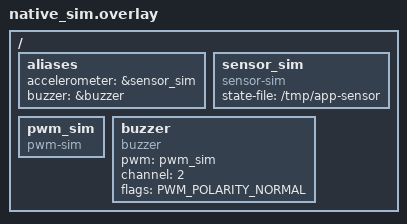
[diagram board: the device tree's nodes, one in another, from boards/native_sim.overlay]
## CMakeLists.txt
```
cmake_minimum_required(VERSION 3.20.0)

find_package(Zephyr REQUIRED HINTS $ENV{ZEPHYR_BASE})
project(workshop)

target_sources(app PRIVATE
    src/main.c
    src/serial_dfu.c
)
```

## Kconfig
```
menu "Application"

config APP_HELLO_WORLD_MSG
	string "Hello World Message"
	default "Hello World!"
	help
	  Customizable hello world message.

endmenu

source "Kconfig.zephyr"
```

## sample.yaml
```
sample:
  name: Workshop application
tests:
  app.renode.buzzer:
    harness: robot
    harness_config:
      robot_testsuite: tests/robot/buzzer.robot
    platform_allow: demo
    tags: renode
```

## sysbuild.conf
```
# Sysbuild configuration: only used when building with --sysbuild (the demo board build).
# These Kconfig options are passed to all images.

SB_CONFIG_BOOTLOADER_MCUBOOT=y
SB_CONFIG_MCUBOOT_MODE_SWAP_SCRATCH=y
SB_CONFIG_BOOT_SIGNATURE_TYPE_ECDSA_P256=y
```

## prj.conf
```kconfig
CONFIG_LOG=y

# USB device stack with a CDC ACM serial port (dfu_uart), enabled at boot
CONFIG_USB_DEVICE_STACK_NEXT=y
CONFIG_USBD_CDC_ACM_CLASS=y
CONFIG_CDC_ACM_SERIAL_INITIALIZE_AT_BOOT=y
CONFIG_CDC_ACM_SERIAL_MANUFACTURER_STRING="Workshop"
CONFIG_CDC_ACM_SERIAL_PRODUCT_STRING="Workshop Demo DFU"
CONFIG_USBD_CDC_ACM_LOG_LEVEL_WRN=y
CONFIG_USBD_LOG_LEVEL_WRN=y

# Firmware update over the USB serial port (src/serial_dfu.c):
# write images to slot1 and hand them over to MCUboot
CONFIG_FLASH=y
CONFIG_FLASH_MAP=y
CONFIG_STREAM_FLASH=y
CONFIG_IMG_MANAGER=y
CONFIG_MCUBOOT_IMG_MANAGER=y
CONFIG_CRC=y
CONFIG_REBOOT=y
```

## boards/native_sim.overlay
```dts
#include <zephyr/dt-bindings/pwm/pwm.h>

/ {
	aliases {
		accelerometer = &sensor_sim;
		buzzer = &buzzer;
	};

	sensor_sim: sensor_sim {
		compatible = "sensor-sim";
		state-file = "/tmp/app-sensor";
		status = "okay";
	};

	pwm_sim: pwm_sim {
		compatible = "pwm-sim";
		status = "okay";
	};

	buzzer: buzzer {
		compatible = "buzzer";
		pwm = <&pwm_sim>;
		channel = <2>;
		flags = <PWM_POLARITY_NORMAL>;
		status = "okay";
	};
};
```

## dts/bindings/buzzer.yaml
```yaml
description: |
  Demonstration of a simple driver to control a buzzer.

compatible: "buzzer"

properties:
  pwm:
    type: phandle
    required: true
    description: |
      PWM to be used for the buzzer.
  
  channel:
    type: int
    required: true

  flags:
    type: int
    required: true
```

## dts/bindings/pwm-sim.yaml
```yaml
description: |
  Simulated PWM output.

compatible: "pwm-sim"
```

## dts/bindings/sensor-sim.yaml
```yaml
description: |
  Simulated sensor.

compatible: "sensor-sim"

properties:
  state-file:
    type: string
    required: true
```

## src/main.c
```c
#include <zephyr/logging/log.h>

LOG_MODULE_REGISTER(main);

int main(void)
{
    while (true) {
        LOG_INF("%s %s", CONFIG_APP_HELLO_WORLD_MSG, CONFIG_BOARD_TARGET);
        k_sleep(K_MSEC(1000));
        k_panic();
    }

    return 0;
}
```

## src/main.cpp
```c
#include "cpp_wrappers/Buzzer.hpp"
#include "cpp_wrappers/Accelerometer.hpp"
#include "cpp_wrappers/Thread.hpp"
#include "cpp_wrappers/SoftwareTimer.hpp"
#include "cpp_wrappers/MessageQueue.hpp"
#include "cpp_wrappers/Semaphore.hpp"
#include <zephyr/logging/log.h>
#include "frequency.h"

#define PWM_CHANNEL 2

LOG_MODULE_REGISTER(main);

static void sensor_timer_callback();
static void sensor_thread_function();
static void buzzer_thread_function();

K_THREAD_STACK_DEFINE(sensor_thread_stack, 1024);
K_THREAD_STACK_DEFINE(buzzer_thread_stack, 1024);

static Thread sensor_thread(sensor_thread_stack, K_THREAD_STACK_SIZEOF(sensor_thread_stack), sensor_thread_function, 5);
static Thread buzzer_thread(buzzer_thread_stack, K_THREAD_STACK_SIZEOF(buzzer_thread_stack), buzzer_thread_function, 5);

static SoftwareTimer sensor_timer(sensor_timer_callback);
static Semaphore sensor_sem(0, 1);
static MessageQueue<float, 3> message_queue;

static Accelerometer accelerometer(DEVICE_DT_GET(DT_ALIAS(accelerometer)));
static Buzzer buzzer(DEVICE_DT_GET(DT_ALIAS(buzzer)));

extern "C" int main(void)
{
    LOG_INF("%s %s", CONFIG_APP_HELLO_WORLD_MSG, CONFIG_BOARD_TARGET);

    sensor_thread.start();
    buzzer_thread.start();

    sensor_timer.start(std::chrono::milliseconds(20));

    return 0;
}

static void sensor_timer_callback()
{
    sensor_sem.give();
}

static void sensor_thread_function()
{
    while (true) {
        sensor_sem.take();
        const float value = accelerometer.read();
        message_queue.put(value);
    }
}

static void buzzer_thread_function()
{
    while (true) {
        const float value = message_queue.get();
        const uint32_t freq = accel_to_freq(value);

        if (freq == 0) {
            buzzer.disable();
        } else {
            buzzer.enable(freq);
        }
    }
}
```

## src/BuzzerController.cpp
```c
#include "BuzzerController.hpp"
#include "frequency.h"

BuzzerController::BuzzerController(Thread &thread, 
                                   MessageQueue<float> &message_queue, 
                                   IBuzzer &buzzer) :
    _thread(thread),
    _message_queue(message_queue),
    _buzzer(buzzer)
{
}

void BuzzerController::start()
{
    _thread.start([this] { thread_main(); });
}

void BuzzerController::thread_main()
{
    while (true) {
        const float value = _message_queue.get();
        const uint32_t freq = accel_to_freq(value);

        if (freq == 0) {
            _buzzer.disable();
        } else {
            _buzzer.enable(freq);
        }
    }
}
```

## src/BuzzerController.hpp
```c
#pragma once

#include "cpp_wrappers/Thread.hpp"
#include "cpp_wrappers/SoftwareTimer.hpp"
#include "cpp_wrappers/Semaphore.hpp"
#include "cpp_wrappers/MessageQueue.hpp"
#include "cpp_wrappers/Buzzer.hpp"

class BuzzerController
{
public:
    BuzzerController(Thread &thread, MessageQueue<float> &message_queue, Buzzer &Buzzer);

    void start();

    BuzzerController(const BuzzerController &) = delete;
    BuzzerController &operator=(const BuzzerController &) = delete;
    BuzzerController(BuzzerController &&) = delete;
    BuzzerController &operator=(BuzzerController &&) = delete;

private:
    Thread &_thread;
    MessageQueue<float> &_message_queue;
    Buzzer &_buzzer;

    void thread_main();
};
```

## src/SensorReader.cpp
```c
#include "SensorReader.hpp"

SensorReader::SensorReader(Thread &thread, MessageQueue<float> &message_queue, Accelerometer &accelerometer) : 
    _thread(thread),
    _message_queue(message_queue),
    _accelerometer(accelerometer),
    _timer([this] { timer_callback(); }),
    _semaphore(0, 1)
{
}

void SensorReader::start()
{
    _thread.start([this] { thread_main(); });
    _timer.start(std::chrono::milliseconds(20));
}

void SensorReader::timer_callback()
{
    _semaphore.give();
}

void SensorReader::thread_main()
{
    while (true) {
        _semaphore.take();
        const float value = _accelerometer.read();
        _message_queue.put(value);
    }
}
```

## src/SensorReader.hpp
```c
#pragma once

#include "cpp_wrappers/Thread.hpp"
#include "cpp_wrappers/SoftwareTimer.hpp"
#include "cpp_wrappers/Semaphore.hpp"
#include "cpp_wrappers/MessageQueue.hpp"
#include "cpp_wrappers/Accelerometer.hpp"

class SensorReader
{
public:
    SensorReader(Thread &thread, MessageQueue<float> &message_queue, Accelerometer &accelerometer);

    void start();

    SensorReader(const SensorReader &) = delete;
    SensorReader &operator=(const SensorReader &) = delete;
    SensorReader(SensorReader &&) = delete;
    SensorReader &operator=(SensorReader &&) = delete;

private:
    Thread &_thread;
    MessageQueue<float> &_message_queue;
    Accelerometer &_accelerometer;

    SoftwareTimer _timer;
    Semaphore _semaphore;

    void timer_callback();
    void thread_main();
};
```

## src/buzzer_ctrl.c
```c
#include "buzzer_ctrl.h"
#include "drivers/buzzer.h"
#include <zephyr/logging/log.h>

LOG_MODULE_REGISTER(buzzer_ctrl);

static void buzzer_thread_function(void *p1, void *p2, void *p3);

K_MSGQ_DEFINE(buzzer_msgq, sizeof(int), 3, 1);
K_THREAD_DEFINE(buzzer_thread, 1024, buzzer_thread_function, NULL, NULL, NULL, 5, 0, 0);

void buzzer_ctrl_post(const struct sensor_value *accel_z)
{
    int ret = k_msgq_put(&buzzer_msgq, accel_z, K_NO_WAIT);

    if (ret != 0) {
        LOG_WRN("k_msgq_put: %d", ret);
    }
}

static void buzzer_thread_function(void *p1, void *p2, void *p3)
{
    ARG_UNUSED(p1);
    ARG_UNUSED(p2);
    ARG_UNUSED(p3);

    const struct device *buzzer_dev = DEVICE_DT_GET(DT_CHOSEN(workshop_buzzer));
    struct sensor_value accel_z;
    int ret = 0;

    while (true) {
        ret = k_msgq_get(&buzzer_msgq, &accel_z, K_FOREVER);

        if (ret != 0) {
            LOG_ERR("k_msgq_get: %d", ret);
            continue;
        }

        buzzer_enable(buzzer_dev, accel_z.val1 < 9);
    }
}
```

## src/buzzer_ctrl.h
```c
#pragma once

#include <zephyr/drivers/sensor.h>

void buzzer_ctrl_post(const struct sensor_value* accel_z);
```

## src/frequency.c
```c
#include "frequency.h"

#define MIN_FREQ   500.0f
#define MAX_FREQ   3000.0f
#define MIN_ACCEL  8.0f
#define MAX_ACCEL  -9.0f

uint32_t accel_to_freq(float accel)
{
    if (accel > MIN_ACCEL) {
        return 0;
    }

    float freq = MIN_FREQ + (accel - MIN_ACCEL) * (MAX_FREQ - MIN_FREQ) / (MAX_ACCEL - MIN_ACCEL);
    return (uint32_t)freq;
}
```

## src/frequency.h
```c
#ifndef FREQUENCY_H
#define FREQUENCY_H

#include <stdint.h>

#ifdef __cplusplus
extern "C" {
#endif

/**
 * Map an acceleration value to a buzzer frequency in Hz.
 *
 * Returns 0 when the buzzer should be off (accel > 8.0).
 * Otherwise returns a value linearly interpolated in [500, 3000] Hz
 * for accel in [8.0, -9.0].
 */
uint32_t accel_to_freq(float accel);

#ifdef __cplusplus
}
#endif

#endif /* FREQUENCY_H */
```

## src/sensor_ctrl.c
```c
#include "sensor_ctrl.h"
#include "buzzer_ctrl.h"
#include <zephyr/kernel.h>
#include <zephyr/logging/log.h>
#include <zephyr/drivers/sensor.h>

LOG_MODULE_REGISTER(sensor_ctrl);

static void sensor_timer_callback(struct k_timer *timer);
static void sensor_thread_function(void *p1, void *p2, void *p3);

K_TIMER_DEFINE(sensor_timer, sensor_timer_callback, NULL);
K_SEM_DEFINE(sensor_sem, 0, 1);
K_THREAD_DEFINE(sensor_thread, 1024, sensor_thread_function, NULL, NULL, NULL, 5, 0, 0);

void sensor_ctrl_start(void)
{
    k_timer_start(&sensor_timer, K_MSEC(10), K_MSEC(10));
}

static void sensor_timer_callback(struct k_timer *timer)
{
    ARG_UNUSED(timer);

    k_sem_give(&sensor_sem);
}

static void sensor_thread_function(void *p1, void *p2, void *p3)
{
    ARG_UNUSED(p1);
    ARG_UNUSED(p2);
    ARG_UNUSED(p3);

    const struct device *sensor_dev = DEVICE_DT_GET(DT_CHOSEN(workshop_sensor));
    struct sensor_value accel_z;
    int ret = 0;

    while (true) {
        k_sem_take(&sensor_sem, K_FOREVER);

        ret = sensor_sample_fetch(sensor_dev);

        if (ret != 0) {
            LOG_ERR("sensor_sample_fetch: %d", ret);
            continue;
        }

        ret = sensor_channel_get(sensor_dev, SENSOR_CHAN_ACCEL_Z, &accel_z);

        if (ret != 0) {
            LOG_ERR("sensor_channel_get: %d", ret);
            continue;
        }

        buzzer_ctrl_post(&accel_z);
    }
}
```

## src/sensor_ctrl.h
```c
#pragma once

void sensor_ctrl_start(void);
```

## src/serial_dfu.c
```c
/*
 * Firmware update over a serial port (demonstrator only).
 *
 * Receives a signed image, stores it in slot1 and requests MCUboot to install
 * it. Host side: scripts/dfu.py
 *
 * Stop-and-wait protocol: the host sends one frame and waits for the response
 * before sending the next one. All multi-byte values are little endian.
 *
 * Request frame (host -> device):
 *   0xA5 | command (u8) | length (u16) | payload (length bytes) | crc32 (u32)
 *   crc32: CRC-32/IEEE (same as Python's zlib.crc32) over command, length and payload
 *
 * Response (device -> host):
 *   0x5A | status (u8)
 *
 * Commands:
 *   START  (0x01): payload = image size (u32). Erases slot1.
 *   DATA   (0x02): payload = offset (u32) + 1..512 data bytes. Offsets must be
 *                  sequential. A repeated last chunk is acknowledged again.
 *   FINISH (0x03): no payload. Marks the image for a test upgrade and reboots.
 *
 * Incomplete frames are discarded after 500 ms without receiving data.
 */

#include "serial_dfu.h"

#include <zephyr/kernel.h>
#include <zephyr/drivers/uart.h>
#include <zephyr/dfu/flash_img.h>
#include <zephyr/dfu/mcuboot.h>
#include <zephyr/storage/flash_map.h>
#include <zephyr/sys/byteorder.h>
#include <zephyr/sys/crc.h>
#include <zephyr/sys/reboot.h>
#include <zephyr/sys/ring_buffer.h>
#include <zephyr/logging/log.h>

LOG_MODULE_REGISTER(serial_dfu);

#define FRAME_START    0xA5
#define RESPONSE_START 0x5A

#define CMD_START  0x01
#define CMD_DATA   0x02
#define CMD_FINISH 0x03

#define MAX_DATA_SIZE    512
#define MAX_PAYLOAD_SIZE (sizeof(uint32_t) + MAX_DATA_SIZE)

enum status {
	STATUS_OK = 0x00,
	STATUS_FRAME_ERROR = 0x01,     /* invalid length or CRC, frame discarded */
	STATUS_INVALID_COMMAND = 0x02, /* unknown command or invalid payload length */
	STATUS_INVALID_STATE = 0x03,   /* DATA/FINISH without START, or FINISH too early */
	STATUS_INVALID_OFFSET = 0x04,  /* DATA offset does not match the bytes received */
	STATUS_INVALID_SIZE = 0x05,    /* image does not fit into slot1, or too much data */
	STATUS_FLASH_ERROR = 0x06,     /* erasing/writing flash or requesting the upgrade failed */
};

#define INTER_BYTE_TIMEOUT K_MSEC(500)

static const struct device *const uart = DEVICE_DT_GET(DT_NODELABEL(dfu_uart));

/* filled by the UART ISR, drained by the thread */
RING_BUF_DECLARE(rx_ring, 1024);
static K_SEM_DEFINE(rx_sem, 0, 1);

/* frame parser */
enum parser_state {
	STATE_WAIT_START,
	STATE_COMMAND,
	STATE_LENGTH_LOW,
	STATE_LENGTH_HIGH,
	STATE_PAYLOAD,
	STATE_CRC,
};

static struct {
	enum parser_state state;
	uint8_t command;
	uint16_t length;
	uint8_t payload[MAX_PAYLOAD_SIZE];
	size_t index;
	uint32_t crc;
	uint32_t received_crc;
} frame;

/* image transfer */
static struct flash_img_context image;
static bool receiving;
static uint32_t image_size;
static uint32_t bytes_received;

static void send_response(enum status status)
{
	uart_poll_out(uart, RESPONSE_START);
	uart_poll_out(uart, status);
}

static enum status handle_start(void)
{
	if (frame.length != sizeof(uint32_t)) {
		return STATUS_INVALID_COMMAND;
	}

	/* (re)start the transfer from scratch */
	receiving = false;

	int ret = flash_img_init(&image);
	if (ret != 0) {
		LOG_ERR("flash_img_init failed (%d)", ret);
		return STATUS_FLASH_ERROR;
	}

	/* the end of the slot is reserved for the MCUboot trailer */
	const size_t slot_size = image.flash_area->fa_size;
	const ssize_t max_size = boot_get_trailer_status_offset(slot_size);
	const uint32_t size = sys_get_le32(frame.payload);

	if (size == 0 || max_size <= 0 || size > (size_t)max_size) {
		LOG_ERR("Invalid image size %u (max %d)", size, (int)max_size);
		return STATUS_INVALID_SIZE;
	}

	LOG_INF("Receiving image of %u bytes, erasing slot1", size);
	ret = flash_area_erase(image.flash_area, 0, slot_size);
	if (ret != 0) {
		LOG_ERR("Erasing slot1 failed (%d)", ret);
		return STATUS_FLASH_ERROR;
	}

	image_size = size;
	bytes_received = 0;
	receiving = true;
	return STATUS_OK;
}

static enum status handle_data(void)
{
	if (frame.length <= sizeof(uint32_t)) {
		return STATUS_INVALID_COMMAND;
	}
	if (!receiving) {
		return STATUS_INVALID_STATE;
	}

	const uint32_t offset = sys_get_le32(frame.payload);
	const uint8_t *data = frame.payload + sizeof(uint32_t);
	const uint32_t len = frame.length - sizeof(uint32_t);

	/* the host repeats a chunk if our response got lost */
	if (offset + len == bytes_received) {
		return STATUS_OK;
	}
	if (offset != bytes_received) {
		LOG_ERR("Unexpected offset %u (expected %u)", offset, bytes_received);
		return STATUS_INVALID_OFFSET;
	}
	if (bytes_received + len > image_size) {
		return STATUS_INVALID_SIZE;
	}

	const int ret = flash_img_buffered_write(&image, data, len, false);
	if (ret != 0) {
		LOG_ERR("Writing image failed (%d)", ret);
		receiving = false;
		return STATUS_FLASH_ERROR;
	}

	bytes_received += len;
	return STATUS_OK;
}

static enum status handle_finish(void)
{
	if (frame.length != 0) {
		return STATUS_INVALID_COMMAND;
	}
	if (!receiving || bytes_received != image_size) {
		return STATUS_INVALID_STATE;
	}
	receiving = false;

	int ret = flash_img_buffered_write(&image, NULL, 0, true);
	if (ret != 0) {
		LOG_ERR("Writing image failed (%d)", ret);
		return STATUS_FLASH_ERROR;
	}

	/* MCUboot verifies the signature on the next boot and swaps the images */
	ret = boot_request_upgrade(BOOT_UPGRADE_TEST);
	if (ret != 0) {
		LOG_ERR("Requesting upgrade failed (%d)", ret);
		return STATUS_FLASH_ERROR;
	}

	LOG_INF("Image received, rebooting to install it");
	send_response(STATUS_OK);

	/* give USB and the deferred logger time to send the last data */
	k_sleep(K_MSEC(500));
	sys_reboot(SYS_REBOOT_COLD);

	return STATUS_OK; /* not reached */
}

static enum status handle_frame(void)
{
	switch (frame.command) {
	case CMD_START:
		return handle_start();
	case CMD_DATA:
		return handle_data();
	case CMD_FINISH:
		return handle_finish();
	default:
		return STATUS_INVALID_COMMAND;
	}
}

static void update_crc(uint8_t byte)
{
	frame.crc = crc32_ieee_update(frame.crc, &byte, 1);
}

/* feeds one received byte into the frame parser, handles complete frames */
static void process_byte(uint8_t byte)
{
	switch (frame.state) {
	case STATE_WAIT_START:
		/* ignore anything between frames */
		if (byte == FRAME_START) {
			frame.crc = 0;
			frame.state = STATE_COMMAND;
		}
		break;

	case STATE_COMMAND:
		update_crc(byte);
		frame.command = byte;
		frame.state = STATE_LENGTH_LOW;
		break;

	case STATE_LENGTH_LOW:
		update_crc(byte);
		frame.length = byte;
		frame.state = STATE_LENGTH_HIGH;
		break;

	case STATE_LENGTH_HIGH:
		update_crc(byte);
		frame.length |= (uint16_t)byte << 8;
		if (frame.length > MAX_PAYLOAD_SIZE) {
			LOG_WRN("Invalid frame length %u", frame.length);
			frame.state = STATE_WAIT_START;
			send_response(STATUS_FRAME_ERROR);
			break;
		}
		frame.index = 0;
		frame.received_crc = 0;
		frame.state = (frame.length > 0) ? STATE_PAYLOAD : STATE_CRC;
		break;

	case STATE_PAYLOAD:
		update_crc(byte);
		frame.payload[frame.index++] = byte;
		if (frame.index == frame.length) {
			frame.index = 0;
			frame.state = STATE_CRC;
		}
		break;

	case STATE_CRC:
		frame.received_crc |= (uint32_t)byte << (8 * frame.index++);
		if (frame.index == sizeof(uint32_t)) {
			frame.state = STATE_WAIT_START;
			if (frame.received_crc == frame.crc) {
				send_response(handle_frame());
			} else {
				LOG_WRN("Invalid frame CRC");
				send_response(STATUS_FRAME_ERROR);
			}
		}
		break;
	}
}

static void uart_isr(const struct device *dev, void *user_data)
{
	ARG_UNUSED(user_data);

	while (uart_irq_update(dev) && uart_irq_rx_ready(dev)) {
		uint8_t buffer[64];
		const int len = uart_fifo_read(dev, buffer, sizeof(buffer));

		if (len <= 0) {
			break;
		}
		/* cannot overflow with the stop-and-wait protocol (one frame in flight) */
		ring_buf_put(&rx_ring, buffer, len);
	}
	k_sem_give(&rx_sem);
}

static void serial_dfu_thread(void *p1, void *p2, void *p3)
{
	ARG_UNUSED(p1);
	ARG_UNUSED(p2);
	ARG_UNUSED(p3);

	LOG_INF("Waiting for firmware image on %s", uart->name);

	while (true) {
		if (k_sem_take(&rx_sem, INTER_BYTE_TIMEOUT) != 0) {
			if (frame.state != STATE_WAIT_START) {
				LOG_WRN("Timeout, discarding incomplete frame");
				frame.state = STATE_WAIT_START;
			}
			continue;
		}

		uint8_t buffer[64];
		uint32_t len;

		while ((len = ring_buf_get(&rx_ring, buffer, sizeof(buffer))) > 0) {
			for (uint32_t i = 0; i < len; i++) {
				process_byte(buffer[i]);
			}
		}
	}
}

K_THREAD_DEFINE(serial_dfu_tid, 2048, serial_dfu_thread, NULL, NULL, NULL, 7, 0,
		SYS_FOREVER_MS);

/*
 * After a test upgrade, MCUboot reverts to the previous image on the next reset
 * unless the new image is confirmed. A real product would only confirm after a
 * successful self test; this demonstrator confirms right away.
 */
static void confirm_running_image(void)
{
	if (boot_is_img_confirmed()) {
		return;
	}

	const int ret = boot_write_img_confirmed();

	if (ret == 0) {
		LOG_INF("Running image confirmed");
	} else {
		LOG_ERR("Failed to confirm running image (%d)", ret);
	}
}

void serial_dfu_start(void)
{
	__ASSERT(device_is_ready(uart), "dfu_uart not ready");

	confirm_running_image();

	uart_irq_callback_user_data_set(uart, uart_isr, NULL);
	uart_irq_rx_enable(uart);

	k_thread_start(serial_dfu_tid);
}
```
